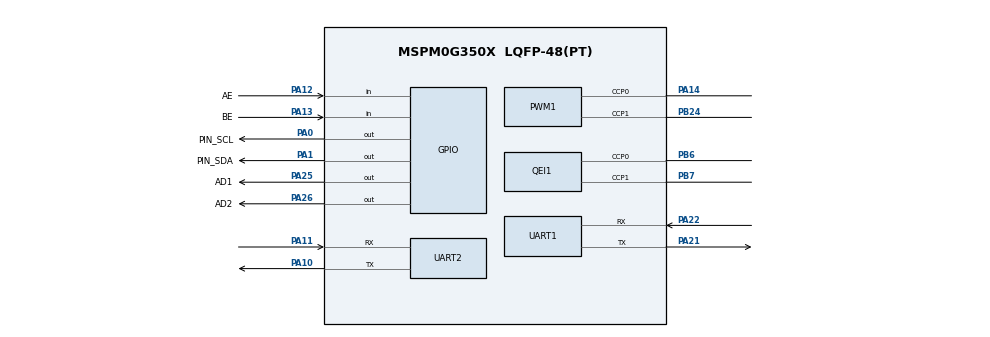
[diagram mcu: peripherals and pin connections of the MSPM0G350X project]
/**
 * @cliArgs --device "MSPM0G350X" --part "Default" --package "LQFP-48(PT)" --product "mspm0_sdk@2.10.00.04"
 * @versions {"tool":"1.26.0+4407"}
 */

/**
 * Import the modules used in this configuration.
 */
const ADC12   = scripting.addModule("/ti/driverlib/ADC12", {}, false);
const ADC121  = ADC12.addInstance();
const GPIO    = scripting.addModule("/ti/driverlib/GPIO", {}, false);
const GPIO1   = GPIO.addInstance();
const GPIO2   = GPIO.addInstance();
const GPIO3   = GPIO.addInstance();
const GPIO4   = GPIO.addInstance();
const GPIO5   = GPIO.addInstance();
const GPIO6   = GPIO.addInstance();
const PWM     = scripting.addModule("/ti/driverlib/PWM", {}, false);
const PWM1    = PWM.addInstance();
const QEI     = scripting.addModule("/ti/driverlib/QEI", {}, false);
const QEI1    = QEI.addInstance();
const SYSCTL  = scripting.addModule("/ti/driverlib/SYSCTL");
const SYSTICK = scripting.addModule("/ti/driverlib/SYSTICK");
const UART    = scripting.addModule("/ti/driverlib/UART", {}, false);
const UART1   = UART.addInstance();
const UART2   = UART.addInstance();

/**
 * Write custom configuration values to the imported modules.
 */
const gate7  = system.clockTree["MFCLKGATE"];
gate7.enable = true;

ADC121.$name                             = "ADC_line_detector";
ADC121.repeatMode                        = true;
ADC121.adcMem0_name                      = "detector_out";
ADC121.sampClkDiv                        = "DL_ADC12_CLOCK_DIVIDE_8";
ADC121.sampleTime0                       = "100us";
ADC121.configureDMA                      = true;
ADC121.sampCnt                           = 1;
ADC121.enabledDMATriggers                = ["DL_ADC12_DMA_MEM0_RESULT_LOADED"];
ADC121.peripheral.$assign                = "ADC0";
ADC121.peripheral.adcPin0.$assign        = "PA27";
ADC121.adcPin0Config.$name               = "ti_driverlib_gpio_GPIOPinGeneric0";
ADC121.adcPin0Config.hideOutputInversion = scripting.forceWrite(false);
ADC121.DMA_CHANNEL.$name                 = "DMA_detector_out";
ADC121.DMA_CHANNEL.srcLength             = "HALF_WORD";
ADC121.DMA_CHANNEL.dstLength             = "HALF_WORD";
ADC121.DMA_CHANNEL.configureTransferSize = true;
ADC121.DMA_CHANNEL.transferMode          = "FULL_CH_REPEAT_SINGLE";
ADC121.DMA_CHANNEL.interruptPriority     = "1";
ADC121.DMA_CHANNEL.peripheral.$assign    = "DMA_CH0";

const Board = scripting.addModule("/ti/driverlib/Board", {}, false);

GPIO1.$name                          = "GPIO_OLED";
GPIO1.port                           = "PORTA";
GPIO1.associatedPins.create(2);
GPIO1.associatedPins[0].$name        = "PIN_SCL";
GPIO1.associatedPins[0].assignedPin  = "0";
GPIO1.associatedPins[0].initialValue = "SET";
GPIO1.associatedPins[0].ioStructure  = "OD";
GPIO1.associatedPins[0].pin.$assign  = "PA0";
GPIO1.associatedPins[1].$name        = "PIN_SDA";
GPIO1.associatedPins[1].initialValue = "SET";
GPIO1.associatedPins[1].ioStructure  = "OD";
GPIO1.associatedPins[1].assignedPin  = "1";
GPIO1.associatedPins[1].pin.$assign  = "PA1";

GPIO2.port                                = "PORTB";
GPIO2.$name                               = "GPIO_KNOB";
GPIO2.associatedPins.create(3);
GPIO2.associatedPins[0].$name             = "A";
GPIO2.associatedPins[0].direction         = "INPUT";
GPIO2.associatedPins[0].interruptEn       = true;
GPIO2.associatedPins[0].polarity          = "FALL";
GPIO2.associatedPins[0].interruptPriority = "2";
GPIO2.associatedPins[0].assignedPin       = "20";
GPIO2.associatedPins[1].$name             = "B";
GPIO2.associatedPins[1].assignedPin       = "19";
GPIO2.associatedPins[1].direction         = "INPUT";
GPIO2.associatedPins[2].$name             = "S";
GPIO2.associatedPins[2].direction         = "INPUT";
GPIO2.associatedPins[2].interruptPriority = "2";
GPIO2.associatedPins[2].assignedPin       = "18";

GPIO3.$name                              = "Gray_Address";
GPIO3.port                               = "PORTA";
GPIO3.associatedPins.create(3);
GPIO3.associatedPins[0].assignedPin      = "24";
GPIO3.associatedPins[0].internalResistor = "PULL_DOWN";
GPIO3.associatedPins[0].$name            = "AD0";
GPIO3.associatedPins[1].$name            = "AD1";
GPIO3.associatedPins[1].internalResistor = "PULL_DOWN";
GPIO3.associatedPins[1].assignedPin      = "25";
GPIO3.associatedPins[1].pin.$assign      = "PA25";
GPIO3.associatedPins[2].$name            = "AD2";
GPIO3.associatedPins[2].internalResistor = "PULL_DOWN";
GPIO3.associatedPins[2].assignedPin      = "26";
GPIO3.associatedPins[2].pin.$assign      = "PA26";

GPIO4.$name                          = "GPIO_MOTOR";
GPIO4.associatedPins.create(4);
GPIO4.associatedPins[0].$name        = "AIN1";
GPIO4.associatedPins[0].assignedPort = "PORTA";
GPIO4.associatedPins[0].assignedPin  = "16";
GPIO4.associatedPins[1].$name        = "AIN2";
GPIO4.associatedPins[1].assignedPort = "PORTA";
GPIO4.associatedPins[1].assignedPin  = "15";
GPIO4.associatedPins[2].$name        = "BIN1";
GPIO4.associatedPins[2].assignedPort = "PORTA";
GPIO4.associatedPins[2].assignedPin  = "17";
GPIO4.associatedPins[3].$name        = "BIN2";
GPIO4.associatedPins[3].assignedPort = "PORTA";
GPIO4.associatedPins[3].assignedPin  = "18";

GPIO5.$name                              = "GPIO_BEEP";
GPIO5.port                               = "PORTA";
GPIO5.associatedPins[0].$name            = "PIN";
GPIO5.associatedPins[0].assignedPin      = "7";
GPIO5.associatedPins[0].internalResistor = "PULL_UP";

GPIO6.$name                               = "GPIO_ENCODER_B";
GPIO6.port                                = "PORTA";
GPIO6.associatedPins.create(2);
GPIO6.associatedPins[0].$name             = "AE";
GPIO6.associatedPins[0].direction         = "INPUT";
GPIO6.associatedPins[0].internalResistor  = "PULL_DOWN";
GPIO6.associatedPins[0].interruptEn       = true;
GPIO6.associatedPins[0].interruptPriority = "2";
GPIO6.associatedPins[0].polarity          = "RISE_FALL";
GPIO6.associatedPins[0].pin.$assign       = "PA12";
GPIO6.associatedPins[1].$name             = "BE";
GPIO6.associatedPins[1].direction         = "INPUT";
GPIO6.associatedPins[1].internalResistor  = "PULL_DOWN";
GPIO6.associatedPins[1].assignedPin       = "13";
GPIO6.associatedPins[1].pin.$assign       = "PA13";

PWM1.$name                      = "PWM_0";
PWM1.timerStartTimer            = true;
PWM1.timerCount                 = 3200;
PWM1.peripheral.$assign         = "TIMG12";
PWM1.peripheral.ccp0Pin.$assign = "PA14";
PWM1.peripheral.ccp1Pin.$assign = "PB24";
PWM1.PWM_CHANNEL_0.$name        = "ti_driverlib_pwm_PWMTimerCC0";
PWM1.PWM_CHANNEL_1.$name        = "ti_driverlib_pwm_PWMTimerCC1";
PWM1.ccp0PinConfig.$name        = "ti_driverlib_gpio_GPIOPinGeneric5";
PWM1.ccp1PinConfig.$name        = "ti_driverlib_gpio_GPIOPinGeneric6";

QEI1.$name                      = "QEI_0";
QEI1.timerStartTimer            = true;
QEI1.peripheral.$assign         = "TIMG8";
QEI1.peripheral.ccp0Pin.$assign = "PB6";
QEI1.peripheral.ccp1Pin.$assign = "PB7";
QEI1.ccp0PinConfig.$name        = "ti_driverlib_gpio_GPIOPinGeneric7";
QEI1.ccp1PinConfig.$name        = "ti_driverlib_gpio_GPIOPinGeneric8";

SYSCTL.forceDefaultClkConfig = true;
SYSCTL.clockTreeEn           = true;

SYSTICK.periodEnable      = true;
SYSTICK.period            = 32000;
SYSTICK.interruptEnable   = true;
SYSTICK.systickEnable     = true;
SYSTICK.interruptPriority = "3";

UART1.$name                            = "UART_UP";
UART1.uartClkSrc                       = "MFCLK";
UART1.targetBaudRate                   = 115200;
UART1.enableDMARX                      = false;
UART1.peripheral.$assign               = "UART2";
UART1.peripheral.rxPin.$assign         = "PA22";
UART1.peripheral.txPin.$assign         = "PA21";
UART1.txPinConfig.direction            = scripting.forceWrite("OUTPUT");
UART1.txPinConfig.hideOutputInversion  = scripting.forceWrite(false);
UART1.txPinConfig.onlyInternalResistor = scripting.forceWrite(false);
UART1.txPinConfig.passedPeripheralType = scripting.forceWrite("Digital");
UART1.txPinConfig.$name                = "ti_driverlib_gpio_GPIOPinGeneric1";
UART1.rxPinConfig.hideOutputInversion  = scripting.forceWrite(false);
UART1.rxPinConfig.onlyInternalResistor = scripting.forceWrite(false);
UART1.rxPinConfig.passedPeripheralType = scripting.forceWrite("Digital");
UART1.rxPinConfig.$name                = "ti_driverlib_gpio_GPIOPinGeneric2";

UART2.$name                            = "UART_0";
UART2.targetBaudRate                   = 115200;
UART2.peripheral.$assign               = "UART0";
UART2.peripheral.rxPin.$assign         = "PA11";
UART2.peripheral.txPin.$assign         = "PA10";
UART2.txPinConfig.direction            = scripting.forceWrite("OUTPUT");
UART2.txPinConfig.hideOutputInversion  = scripting.forceWrite(false);
UART2.txPinConfig.onlyInternalResistor = scripting.forceWrite(false);
UART2.txPinConfig.passedPeripheralType = scripting.forceWrite("Digital");
UART2.txPinConfig.$name                = "ti_driverlib_gpio_GPIOPinGeneric3";
UART2.rxPinConfig.hideOutputInversion  = scripting.forceWrite(false);
UART2.rxPinConfig.onlyInternalResistor = scripting.forceWrite(false);
UART2.rxPinConfig.passedPeripheralType = scripting.forceWrite("Digital");
UART2.rxPinConfig.$name                = "ti_driverlib_gpio_GPIOPinGeneric4";

const ProjectConfig              = scripting.addModule("/ti/project_config/ProjectConfig", {}, false);
ProjectConfig.migrationCondition = true;

/**
 * Pinmux solution for unlocked pins/peripherals. This ensures that minor changes to the automatic solver in a future
 * version of the tool will not impact the pinmux you originally saw.  These lines can be completely deleted in order to
 * re-solve from scratch.
 */
Board.peripheral.$suggestSolution            = "DEBUGSS";
Board.peripheral.swclkPin.$suggestSolution   = "PA20";
Board.peripheral.swdioPin.$suggestSolution   = "PA19";
GPIO2.associatedPins[0].pin.$suggestSolution = "PB20";
GPIO2.associatedPins[1].pin.$suggestSolution = "PB19";
GPIO2.associatedPins[2].pin.$suggestSolution = "PB18";
GPIO3.associatedPins[0].pin.$suggestSolution = "PA24";
GPIO4.associatedPins[0].pin.$suggestSolution = "PA16";
GPIO4.associatedPins[1].pin.$suggestSolution = "PA15";
GPIO4.associatedPins[2].pin.$suggestSolution = "PA17";
GPIO4.associatedPins[3].pin.$suggestSolution = "PA18";
GPIO5.associatedPins[0].pin.$suggestSolution = "PA7";
